AUTOSAR XML (schema 4-3-0)
# \copyright BMW AG 2015 - 2017
package /BMW/Platform/Rmh/SwComponentTypes
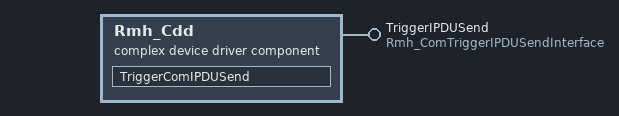
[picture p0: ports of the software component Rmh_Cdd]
  complex device driver sw component type Rmh_Cdd
    provide port TriggerIPDUSend: provided-interface=Rmh_ComTriggerIPDUSendInterface
    behavior InternalBehavior: handle-termination-and-restart=NO-SUPPORT, port-api-option{enable-take-address=false, indirect-api=false, port=TriggerIPDUSend}
      operation invoked event OperationInvokedEvent: start-on-event=TriggerComIPDUSend, operation=TriggerIPDUSend.Rmh_TriggerComIPDUSend
      runnable TriggerComIPDUSend: symbol=Rmh_TriggerComIPDUSend
package /BMW/Platform/Rmh/SwcImplementations
  swc implementation Rmh_Cdd_Implementation: programming-language=C, sw-version=5.0.0, vendor-id=5, behavior=InternalBehavior
    code-descriptors:
      code CodeDescriptor: artifact-descriptors=autosar-engineering-object={short-label=EngObject, category=SWSRC}
    resource consumption Resources
